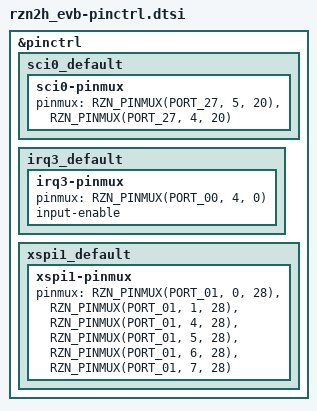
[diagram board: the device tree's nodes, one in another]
/*
 * Copyright (c) 2026 Renesas Electronics Corporation
 * SPDX-License-Identifier: Apache-2.0
 */

#include <zephyr/dt-bindings/gpio/gpio.h>
#include <zephyr/dt-bindings/pinctrl/renesas/pinctrl-rzn-common.h>

&pinctrl {
	/omit-if-no-ref/ sci0_default: sci0_default {
		sci0-pinmux {
			pinmux = <RZN_PINMUX(PORT_27, 5, 20)>, /* TXD */
				 <RZN_PINMUX(PORT_27, 4, 20)>; /* RXD */
		};
	};

	/omit-if-no-ref/ irq3_default: irq3_default {
		irq3-pinmux {
			pinmux = <RZN_PINMUX(PORT_00, 4, 0)>;
			input-enable;
		};
	};

	/omit-if-no-ref/ xspi1_default: xspi1_default {
		xspi1-pinmux {
			pinmux = <RZN_PINMUX(PORT_01, 0, 28)>, /* XSPI1_CKP */
				 <RZN_PINMUX(PORT_01, 1, 28)>, /* XSPI1_CS0 */
				 <RZN_PINMUX(PORT_01, 4, 28)>, /* XSPI1_IO0 */
				 <RZN_PINMUX(PORT_01, 5, 28)>, /* XSPI1_IO1 */
				 <RZN_PINMUX(PORT_01, 6, 28)>, /* XSPI1_IO2 */
				 <RZN_PINMUX(PORT_01, 7, 28)>; /* XSPI1_IO3 */
		};
	};
};
